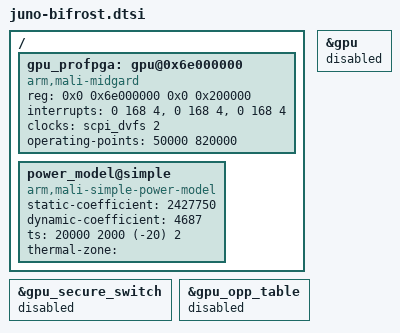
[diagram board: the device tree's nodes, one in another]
/*
 * ARM Ltd. Juno Platform
 *
 * Copyright (c) 2017 ARM Ltd.
 *
 * This file is licensed under a dual GPLv2 or BSD license.
 */

#include "juno-fpga.dtsi"

/ {
	gpu_profpga: gpu@0x6e000000 {
		compatible = "arm,mali-midgard";
		reg = <0x0 0x6e000000 0x0 0x200000>;
		interrupts = <0 168 4>, <0 168 4>, <0 168 4>;
		interrupt-names = "JOB", "MMU", "GPU";
		clocks = <&scpi_dvfs 2>;
		clock-names = "clk_mali";
		operating-points = <
			/* KHz uV */
			50000 820000
		>;
	};

	power_model@simple {
		compatible = "arm,mali-simple-power-model";
		static-coefficient = <2427750>;
		dynamic-coefficient = <4687>;
		ts = <20000 2000 (-20) 2>;
		thermal-zone = "";
	};
};

&gpu_secure_switch {
	status = "disabled";
};

&gpu_opp_table {
	status = "disabled";
};

&gpu {
	status = "disabled";
};
